// Description: LIN Description file created using VDE

// Created: 04/18/2025 14:02:16

// Author: VDE

LIN_description_file;
LIN_protocol_version = "2.1";
LIN_language_version = "2.1";
LIN_speed = 19.2 kbps;

Nodes {
  Master: VDCU, 10 ms, 0.1 ms ;
  Slaves: RLS, SWS, SGM_S, SGM_IP ;
}

Signals {
  BCM_Dimm_Swt: 4, 10, VDCU, SGM_S, SGM_IP;//Dimmer Switch
  BCM_AirHornSetSts_Sts: 1, 0, VDCU, SGM_IP;//Gas Horn status
  BCM_Temp_Cabin_Slpr: 8, 255, VDCU, SGM_S;//后空调室内温度采集信号 温度范围在-40~100
  BCM_RearHeadlight_Sts: 1, 0, VDCU, SGM_IP;//Rear Light status
  BCM_ACFrontDefrostDisp_Sts: 2, 0, VDCU, SGM_IP;//AC Front Defrost status
  ACBlowerLevelDisp: 4, 0, VDCU, SGM_IP;//风量档位显示
  BCM_PosnLigjtReq_Sts: 1, 0, VDCU, SGM_S, SGM_IP;//Position lamp status
  BCM_ACOffDisp_Sts: 2, 0, VDCU, SGM_S;//AC off status
  BCM_ACTimingRunDisp_Sts: 2, 0, VDCU, SGM_S;//AC Timing Run status
  BCM_ADAS_Sts: 3, 0, VDCU;//ADAS lamp status
  BCM_Status_IGN: 2, 0, VDCU, RLS;//Ignition status 点火开关状态
  BCM_CMD_AutoWiper: 1, 0, VDCU, RLS;//Wiper Switch Auto Enabled 雨刮开关处于自动档位置
  BCM_RQ_FrontWash: 1, 0, VDCU, RLS;//Front Washer Switch is Activated 前洗涤开关处于激活状态
  BCM_ParkPosition: 1, 0, VDCU, RLS;//This signal is set when the wiper blade is in park position. This signal is used by the Sensor to mask overwipes and to check that the wiper motor reacts to the commands from the sensor. 这个信号表示雨刮处于停止位置。这个信号被传感器用来屏蔽过度刮刷，并且确认电机是按照雨量的命令工作的。(此信号在离开ParkPosition或者到达ParkPosition时发出延迟小于100ms)
  BCM_RainSensitivity: 3, 0, VDCU, RLS;//rain sensor sensitivity volume 雨量灵敏度
  BCM_CMD_AutoLight: 1, 0, VDCU, RLS;//Light Switch Auto Enabled 灯光开关处于自动档位置
  BCM_BladesTurningPoint: 1, 0, VDCU, RLS;//This signal is set when the wiper blade is in TurningPoint position. This signal is used by the Sensor to mask overwipes and to check that the wiper motor reacts to the commands from the sensor. 雨刮电机远离停止位置的换向点。
  BCM_SPD_Vehicle: 13, 8190, VDCU, RLS;//Current Vehicle Speed 当前车速
  RLS_MsgCounter: 4, 0, RLS, VDCU;//This is a counter, which will be increased after having sent a message to BCM succesfully 这是一个计数器,当RLS每成功发送给BCM一个消息，就增加1
  RLS_RQ_WiperSPD: 2, 0, RLS, VDCU;//The Sensor requested wiper speed 雨量传感器请求的雨刮速度.
  RLS_RQ_LowBeam: 1, 0, RLS, VDCU;//Auto low beam request 近光灯点亮请求
  RLS_RQ_PositionLamp: 1, 0, RLS, VDCU;//Auto position lamp request 位置灯点亮请求
  RLS_Fault_Rain: 1, 0, RLS, VDCU;//Rain sensor fault status 雨量传感器故障状态
  RLS_Fault_Light: 1, 0, RLS, VDCU;//Light sensor fault status 光亮传感器故障状态
  RLS_REP_Error: 1, 0, RLS, VDCU;//RLS LIN response error RLS通讯故障状态
  RLS_VOLT_Error: 2, 0, RLS, VDCU;//RLS Voltage error RLS检测电池电压错误
  RLS_Brightness_FW: 10, 1023, RLS, VDCU;//The Visible Ambientlight (540nm) measured by Spot FW 可见环境光亮度
  RLS_Rain_Intensity: 4, 0, RLS, VDCU;//This signal delivers information about rain intensity: from 0%(no rain) to 100% (very heavy rain) 降雨强度：从0%到100%
  RLS_BigLamp_Threshold_Nr: 10, 0, RLS, VDCU;//大灯开启阀值信号
  RLS_RainCloseWin_Str: 1, 0, RLS, VDCU;//雨天关窗信号
  RLS_WiperSPD_FuncErr: 2, 0, RLS, VDCU;//雨刮功能安全故障
  RLS_RQ_LowBeam_FuncErr: 2, 0, RLS, VDCU;//近光灯功能安全故障
  RLS_CheckSum: 8, 0, RLS, VDCU;//E2E Checksum
  SGM_S_Unlock_Swt: 2, 0, SGM_S, VDCU;//The Switch of the Unlock
  SGM_S_Lock_Swt: 2, 0, SGM_S, VDCU;//The Switch of the Lock
  SGM_S_WLM_FL_Swt: 3, 0, SGM_S, VDCU;//The Switch of the window
  SGM_S_WLM_FR_Swt: 3, 0, SGM_S, VDCU;//The Switch of the window
  SGM_S_VolumePlus_Swt: 2, 0, SGM_S, VDCU;//The Switch of the AC Volume plus
  SGM_S_VolumeMinus_Swt: 2, 0, SGM_S, VDCU;//The Switch of the AC Volume minus
  SGM_S_ACOnOrOff_Swt: 2, 0, SGM_S, VDCU;//The Switch of the AC on or off
  SGM_S_BlowerLvlPlus_Swt: 2, 0, SGM_S, VDCU;//The Switch of the AC Blowe plus
  SGM_S_BlowerLvlMinus_Swt: 2, 0, SGM_S, VDCU;//The Switch of the AC Blowe minus
  SGM_S_ACTempPlus_Swt: 2, 0, SGM_S, VDCU;//The Switch of the AC Temperature plus
  SGM_S_ACTempMinus_Swt: 2, 0, SGM_S, VDCU;//The Switch of the AC Temperature minus
  SGM_S_ACTimingRun_Swt: 2, 0, SGM_S, VDCU;//The Switch of the AC Timing Run
  SGM_S_CMSStart_Swt: 2, 0, SGM_S, VDCU;//The Switch of the CMS start
  SGM_S_F_LINError: 1, 0, SGM_S, VDCU;//This signal shows one or more failures related to LIN communication.
  SGM_IP_HornType_Swt: 2, 0, SGM_IP, VDCU;//The Switch of the Horn Type
  SGM_IP_RearLight_Swt: 2, 0, SGM_IP, VDCU;//The Switch of the Rear light
  SGM_IP_ACOff_Swt: 2, 0, SGM_IP, VDCU;//The Switch of the AC off
  SGM_IP_BlowerLvlPlus_Swt: 2, 0, SGM_IP, VDCU;//The Switch of the AC Blowe plus
  SGM_IP_BlowerLvlMinus_Swt: 2, 0, SGM_IP, VDCU;//The Switch of the AC Blowe minus
  SGM_IP_ACTempPlus_Swt: 2, 0, SGM_IP, VDCU;//The Switch of the AC Temperature plus
  SGM_IP_ACTempMinus_Swt: 2, 0, SGM_IP, VDCU;//The Switch of the AC Temperature minus
  SGM_IP_ACFrontDefrost_Swt: 2, 0, SGM_IP, VDCU;//The Switch of the AC Front Defrost
  SGM_IP_F_LINError: 1, 0, SGM_IP, VDCU;//This signal shows one or more failures related to LIN communication.
}

Frames {
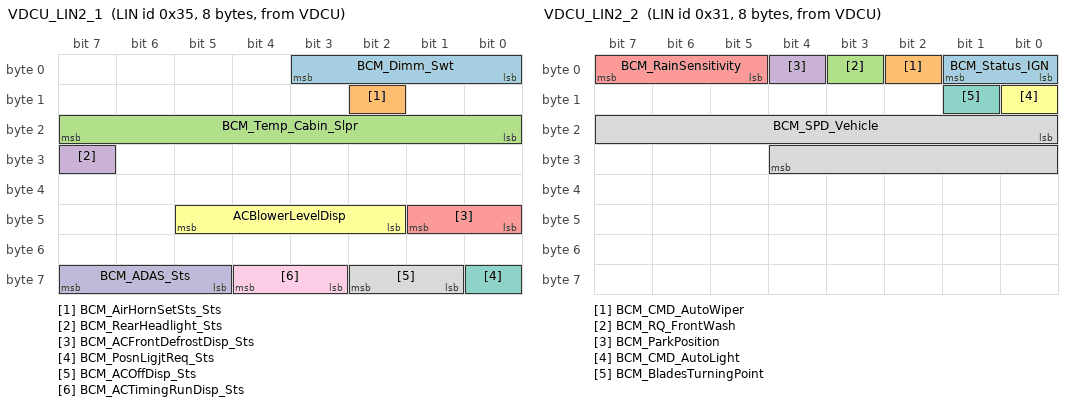
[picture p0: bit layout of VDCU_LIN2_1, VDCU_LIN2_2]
  VDCU_LIN2_1: 0x35, VDCU, 8 {
    BCM_Dimm_Swt, 0 ;
    BCM_AirHornSetSts_Sts, 10 ;
    BCM_Temp_Cabin_Slpr, 16 ;
    BCM_RearHeadlight_Sts, 31 ;
    BCM_ACFrontDefrostDisp_Sts, 40 ;
    ACBlowerLevelDisp, 42 ;
    BCM_PosnLigjtReq_Sts, 56 ;
    BCM_ACOffDisp_Sts, 57 ;
    BCM_ACTimingRunDisp_Sts, 59 ;
    BCM_ADAS_Sts, 61 ;
  }
  VDCU_LIN2_2: 0x31, VDCU, 8 {
    BCM_Status_IGN, 0 ;
    BCM_CMD_AutoWiper, 2 ;
    BCM_RQ_FrontWash, 3 ;
    BCM_ParkPosition, 4 ;
    BCM_RainSensitivity, 5 ;
    BCM_CMD_AutoLight, 8 ;
    BCM_BladesTurningPoint, 9 ;
    BCM_SPD_Vehicle, 16 ;
  }
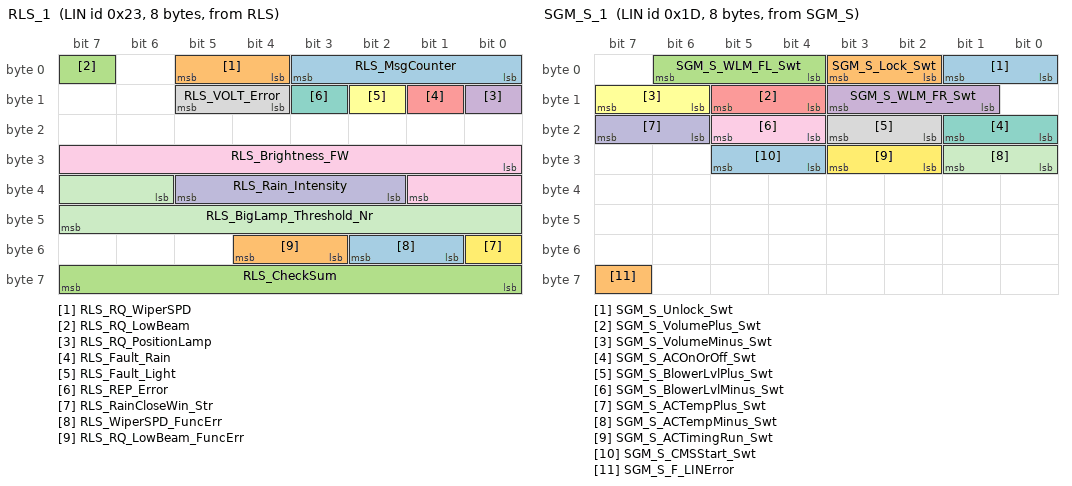
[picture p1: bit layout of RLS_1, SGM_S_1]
  RLS_1: 0x23, RLS, 8 {
    RLS_MsgCounter, 0 ;
    RLS_RQ_WiperSPD, 4 ;
    RLS_RQ_LowBeam, 7 ;
    RLS_RQ_PositionLamp, 8 ;
    RLS_Fault_Rain, 9 ;
    RLS_Fault_Light, 10 ;
    RLS_REP_Error, 11 ;
    RLS_VOLT_Error, 12 ;
    RLS_Brightness_FW, 24 ;
    RLS_Rain_Intensity, 34 ;
    RLS_BigLamp_Threshold_Nr, 38 ;
    RLS_RainCloseWin_Str, 48 ;
    RLS_WiperSPD_FuncErr, 49 ;
    RLS_RQ_LowBeam_FuncErr, 51 ;
    RLS_CheckSum, 56 ;
  }
  SGM_S_1: 0x1D, SGM_S, 8 {
    SGM_S_Unlock_Swt, 0 ;
    SGM_S_Lock_Swt, 2 ;
    SGM_S_WLM_FL_Swt, 4 ;
    SGM_S_WLM_FR_Swt, 9 ;
    SGM_S_VolumePlus_Swt, 12 ;
    SGM_S_VolumeMinus_Swt, 14 ;
    SGM_S_ACOnOrOff_Swt, 16 ;
    SGM_S_BlowerLvlPlus_Swt, 18 ;
    SGM_S_BlowerLvlMinus_Swt, 20 ;
    SGM_S_ACTempPlus_Swt, 22 ;
    SGM_S_ACTempMinus_Swt, 24 ;
    SGM_S_ACTimingRun_Swt, 26 ;
    SGM_S_CMSStart_Swt, 28 ;
    SGM_S_F_LINError, 63 ;
  }
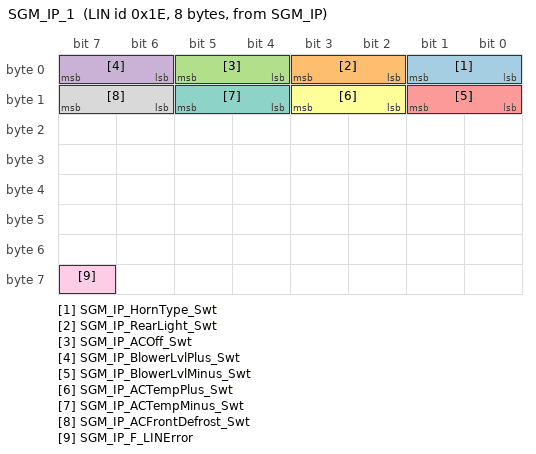
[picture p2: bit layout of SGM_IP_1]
  SGM_IP_1: 0x1E, SGM_IP, 8 {
    SGM_IP_HornType_Swt, 0 ;
    SGM_IP_RearLight_Swt, 2 ;
    SGM_IP_ACOff_Swt, 4 ;
    SGM_IP_BlowerLvlPlus_Swt, 6 ;
    SGM_IP_BlowerLvlMinus_Swt, 8 ;
    SGM_IP_ACTempPlus_Swt, 10 ;
    SGM_IP_ACTempMinus_Swt, 12 ;
    SGM_IP_ACFrontDefrost_Swt, 14 ;
    SGM_IP_F_LINError, 63 ;
  }
}

Node_attributes {
  RLS{
    LIN_protocol = "2.1" ;
    configured_NAD = 35 ;
    initial_NAD = 35 ;
    product_id = 0x0, 0x0, 0 ;
    response_error = RLS_REP_Error ;
    P2_min = 50 ms ;
    ST_min = 0 ms ;
    N_As_timeout = 1000 ms ;
    N_Cr_timeout = 1000 ms ;
    configurable_frames {
      RLS_1 ;
      VDCU_LIN2_2 ;
    }
  }
  SWS{
    LIN_protocol = "2.1" ;
    configured_NAD = 24 ;
    initial_NAD = 24 ;
    product_id = 0x0, 0x0, 0 ;
    P2_min = 50 ms ;
    ST_min = 0 ms ;
    N_As_timeout = 1000 ms ;
    N_Cr_timeout = 1000 ms ;
  }
  SGM_S{
    LIN_protocol = "2.1" ;
    configured_NAD = 29 ;
    initial_NAD = 29 ;
    product_id = 0x0, 0x0, 0 ;
    response_error = SGM_S_F_LINError ;
    P2_min = 50 ms ;
    ST_min = 0 ms ;
    N_As_timeout = 1000 ms ;
    N_Cr_timeout = 1000 ms ;
    configurable_frames {
      SGM_S_1 ;
      VDCU_LIN2_1 ;
    }
  }
  SGM_IP{
    LIN_protocol = "2.1" ;
    configured_NAD = 30 ;
    initial_NAD = 30 ;
    product_id = 0x0, 0x0, 0 ;
    response_error = SGM_IP_F_LINError ;
    P2_min = 50 ms ;
    ST_min = 0 ms ;
    N_As_timeout = 1000 ms ;
    N_Cr_timeout = 1000 ms ;
    configurable_frames {
      SGM_IP_1 ;
      VDCU_LIN2_1 ;
    }
  }
}

Schedule_tables {
 Beacon_LIN1 {
    VDCU_LIN2_1 delay 10 ms ;
    VDCU_LIN2_2 delay 10 ms ;
    SGM_IP_1 delay 10 ms ;
    VDCU_LIN2_2 delay 10 ms ;
    RLS_1 delay 10 ms ;
    SGM_S_1 delay 10 ms ;
  }
}

Signal_encoding_types {
  Enc_VDCU_LIN2_1_BCM_Dimm_Swt {
    physical_value, 0, 10, 10, 0 ;
    logical_value, 0, "Not Request" ;
    logical_value, 1, "10%~100%" ;
    logical_value, 2, "10%~100%" ;
    logical_value, 3, "10%~100%" ;
    logical_value, 4, "10%~100%" ;
    logical_value, 5, "10%~100%" ;
    logical_value, 6, "10%~100%" ;
    logical_value, 7, "10%~100%" ;
    logical_value, 8, "10%~100%" ;
    logical_value, 9, "10%~100%" ;
    logical_value, 10, "10%~100%" ;
    logical_value, 11, "Reserved" ;
    logical_value, 12, "Reserved" ;
    logical_value, 13, "Reserved" ;
    logical_value, 14, "Reserved" ;
    logical_value, 15, "Reserved" ;
  }
  Enc_VDCU_LIN2_1_BCM_AirHornSetSts_Sts {
    physical_value, 0, 1, 1, 0 ;
    logical_value, 0, "ElectricHorn" ;
    logical_value, 1, "AirHorn" ;
  }
  Enc_VDCU_LIN2_1_BCM_Temp_Cabin_Slpr {
    physical_value, 0, 254, 0.5, -40, "℃" ;
  }
  Enc_VDCU_LIN2_1_BCM_RearHeadlight_Sts {
    physical_value, 0, 1, 1, 0 ;
    logical_value, 0, "Lamp Off" ;
    logical_value, 1, "Lamp On" ;
  }
  Enc_VDCU_LIN2_1_BCM_ACFrontDefrostDisp_Sts {
    physical_value, 0, 3, 1, 0 ;
    logical_value, 0, "TakeNoAction" ;
    logical_value, 1, "Off" ;
    logical_value, 2, "On" ;
    logical_value, 3, "Reserved" ;
  }
  Enc_VDCU_LIN2_1_ACBlowerLevelDisp {
    physical_value, 0, 15, 1, 0, "0" ;
  }
  Enc_VDCU_LIN2_1_BCM_PosnLigjtReq_Sts {
    physical_value, 0, 1, 1, 0 ;
    logical_value, 0, "OFF" ;
    logical_value, 1, "ON" ;
  }
  Enc_VDCU_LIN2_1_BCM_ACOffDisp_Sts {
    physical_value, 0, 3, 1, 0 ;
    logical_value, 0, "TakeNoAction" ;
    logical_value, 1, "Off" ;
    logical_value, 2, "On" ;
    logical_value, 3, "Reserved" ;
  }
  Enc_VDCU_LIN2_1_BCM_ACTimingRunDisp_Sts {
    physical_value, 0, 3, 1, 0 ;
    logical_value, 0, "TakeNoAction" ;
    logical_value, 1, "Off" ;
    logical_value, 2, "On" ;
    logical_value, 3, "Reserved" ;
  }
  Enc_VDCU_LIN2_1_BCM_ADAS_Sts {
    physical_value, 0, 7, 1, 0 ;
    logical_value, 0, "Manual" ;
    logical_value, 1, "Auto1（12V_EHPS）" ;
    logical_value, 2, "Auto1（24V_EHPS）" ;
    logical_value, 3, "Reserved" ;
    logical_value, 4, "Reserved" ;
    logical_value, 5, "Reserved" ;
    logical_value, 6, "Reserved" ;
    logical_value, 7, "Reserved" ;
  }
  Enc_VDCU_LIN2_2_BCM_Status_IGN {
    physical_value, 0, 3, 1, 0 ;
    logical_value, 0, "OFF" ;
    logical_value, 1, "ACC" ;
    logical_value, 2, "IGN ON" ;
    logical_value, 3, "IGN Start" ;
  }
  Enc_VDCU_LIN2_2_BCM_CMD_AutoWiper {
    physical_value, 0, 1, 1, 0 ;
    logical_value, 0, "OFF" ;
    logical_value, 1, "ON" ;
  }
  Enc_VDCU_LIN2_2_BCM_RQ_FrontWash {
    physical_value, 0, 1, 1, 0 ;
    logical_value, 0, "No RQ" ;
    logical_value, 1, "RQ FrontWash" ;
  }
  Enc_VDCU_LIN2_2_BCM_ParkPosition {
    physical_value, 0, 1, 1, 0 ;
    logical_value, 0, "Stop not in parking postion" ;
    logical_value, 1, "Stop in parking postion" ;
  }
  Enc_VDCU_LIN2_2_BCM_RainSensitivity {
    physical_value, 0, 7, 1, 0 ;
    logical_value, 0, "Most Insensitive" ;
    logical_value, 1, "More Insensitive" ;
    logical_value, 2, "Insensitive" ;
    logical_value, 3, "Normal" ;
    logical_value, 4, "Sensitive" ;
    logical_value, 5, "More Sensitive(reserved)" ;
    logical_value, 6, "Most Sensitive(reserved)" ;
    logical_value, 7, "Reserved" ;
  }
  Enc_VDCU_LIN2_2_BCM_CMD_AutoLight {
    physical_value, 0, 1, 1, 0 ;
    logical_value, 0, "OFF" ;
    logical_value, 1, "ON" ;
  }
  Enc_VDCU_LIN2_2_BCM_BladesTurningPoint {
    physical_value, 0, 1, 1, 0 ;
    logical_value, 0, "Stop not in TurnPointg pos" ;
    logical_value, 1, "Stop in TurnPoint pos" ;
  }
  Enc_VDCU_LIN2_2_BCM_SPD_Vehicle {
    physical_value, 0, 4800, 0.05625, 0, "Km/h" ;
    logical_value, 8191, "invalid" ;
  }
  Enc_RLS_1_RLS_MsgCounter {
    physical_value, 0, 15, 1, 0 ;
  }
  Enc_RLS_1_RLS_RQ_WiperSPD {
    physical_value, 0, 3, 1, 0 ;
    logical_value, 0, "No wiping" ;
    logical_value, 1, "Low Speed" ;
    logical_value, 2, "High Speed" ;
    logical_value, 3, "Not used" ;
  }
  Enc_RLS_1_RLS_RQ_LowBeam {
    physical_value, 0, 1, 1, 0 ;
    logical_value, 0, "No RQ on Low Beam" ;
    logical_value, 1, "RQ on Low Beam" ;
  }
  Enc_RLS_1_RLS_RQ_PositionLamp {
    physical_value, 0, 1, 1, 0 ;
    logical_value, 0, "No RQ on Position Lamp" ;
    logical_value, 1, "RQ on Position Lamp" ;
  }
  Enc_RLS_1_RLS_Fault_Rain {
    physical_value, 0, 1, 1, 0 ;
    logical_value, 0, "Normal Status" ;
    logical_value, 1, "Status Fault" ;
  }
  Enc_RLS_1_RLS_Fault_Light {
    physical_value, 0, 1, 1, 0 ;
    logical_value, 0, "Normal Status" ;
    logical_value, 1, "Status Fault" ;
  }
  Enc_RLS_1_RLS_REP_Error {
    physical_value, 0, 1, 1, 0 ;
    logical_value, 0, "No error" ;
    logical_value, 1, "Error" ;
  }
  Enc_RLS_1_RLS_VOLT_Error {
    physical_value, 0, 3, 1, 0 ;
    logical_value, 0, "No error" ;
    logical_value, 1, "VOLT_Low" ;
    logical_value, 2, "VOLT_High" ;
    logical_value, 3, "Not used" ;
  }
  Enc_RLS_1_RLS_Brightness_FW {
    physical_value, 0, 1021, 6, 0, "LUX" ;
  }
  Enc_RLS_1_RLS_Rain_Intensity {
    physical_value, 0, 10, 10, 0, "%" ;
  }
  Enc_RLS_1_RLS_BigLamp_Threshold_Nr {
    physical_value, 0, 1021, 6, 0, "LUX" ;
  }
  Enc_RLS_1_RLS_RainCloseWin_Str {
    physical_value, 0, 1, 1, 0 ;
    logical_value, 0, "不关窗" ;
    logical_value, 1, "关窗" ;
  }
  Enc_RLS_1_RLS_WiperSPD_FuncErr {
    physical_value, 0, 3, 1, 0 ;
    logical_value, 0, "正常；" ;
    logical_value, 1, "单点故障（含开关采集类故障、逻辑处理类故障、通讯类故障、驱动类故障等直接影响了功能表现行为的故障）；" ;
    logical_value, 2, "潜伏故障；" ;
    logical_value, 3, "预留。" ;
  }
  Enc_RLS_1_RLS_RQ_LowBeam_FuncErr {
    physical_value, 0, 3, 1, 0 ;
    logical_value, 0, "正常；" ;
    logical_value, 1, "单点故障（含开关采集类故障、逻辑处理类故障、通讯类故障、驱动类故障等直接影响了功能表现行为的故障）；" ;
    logical_value, 2, "潜伏故障；" ;
    logical_value, 3, "预留。" ;
  }
  Enc_RLS_1_RLS_CheckSum {
    physical_value, 0, 255, 1, 0 ;
  }
  Enc_SGM_S_1_SGM_S_Unlock_Swt {
    physical_value, 0, 3, 1, 0 ;
    logical_value, 0, "Not press" ;
    logical_value, 1, "press" ;
    logical_value, 2, "Reserved" ;
    logical_value, 3, "Error" ;
  }
  Enc_SGM_S_1_SGM_S_Lock_Swt {
    physical_value, 0, 3, 1, 0 ;
    logical_value, 0, "Not press" ;
    logical_value, 1, "press" ;
    logical_value, 2, "Reserved" ;
    logical_value, 3, "Error" ;
  }
  Enc_SGM_S_1_SGM_S_WLM_FL_Swt {
    physical_value, 0, 7, 1, 0 ;
    logical_value, 0, "No request" ;
    logical_value, 1, "Driver side driver window manual up" ;
    logical_value, 2, "Driver side driver window manual down" ;
    logical_value, 3, "Driver side driver window auto up" ;
    logical_value, 4, "Driver side driver window auto down" ;
    logical_value, 5, "Reserved" ;
    logical_value, 6, "故障" ;
    logical_value, 7, "无效" ;
  }
  Enc_SGM_S_1_SGM_S_WLM_FR_Swt {
    physical_value, 0, 7, 1, 0 ;
    logical_value, 0, "No request" ;
    logical_value, 1, "Driver side driver window manual up" ;
    logical_value, 2, "Driver side driver window manual down" ;
    logical_value, 3, "Driver side driver window auto up" ;
    logical_value, 4, "Driver side driver window auto down" ;
    logical_value, 5, "Reserved" ;
    logical_value, 6, "故障" ;
    logical_value, 7, "无效" ;
  }
  Enc_SGM_S_1_SGM_S_VolumePlus_Swt {
    physical_value, 0, 3, 1, 0 ;
    logical_value, 0, "Not press" ;
    logical_value, 1, "shortpress" ;
    logical_value, 2, "longpress" ;
    logical_value, 3, "Error" ;
  }
  Enc_SGM_S_1_SGM_S_VolumeMinus_Swt {
    physical_value, 0, 3, 1, 0 ;
    logical_value, 0, "Not press" ;
    logical_value, 1, "shortpress" ;
    logical_value, 2, "longpress" ;
    logical_value, 3, "Error" ;
  }
  Enc_SGM_S_1_SGM_S_ACOnOrOff_Swt {
    physical_value, 0, 3, 1, 0 ;
    logical_value, 0, "Not press" ;
    logical_value, 1, "press" ;
    logical_value, 2, "Reserved" ;
    logical_value, 3, "Error" ;
  }
  Enc_SGM_S_1_SGM_S_BlowerLvlPlus_Swt {
    physical_value, 0, 3, 1, 0 ;
    logical_value, 0, "Not press" ;
    logical_value, 1, "press" ;
    logical_value, 2, "Reserved" ;
    logical_value, 3, "Error" ;
  }
  Enc_SGM_S_1_SGM_S_BlowerLvlMinus_Swt {
    physical_value, 0, 3, 1, 0 ;
    logical_value, 0, "Not press" ;
    logical_value, 1, "press" ;
    logical_value, 2, "Reserved" ;
    logical_value, 3, "Error" ;
  }
  Enc_SGM_S_1_SGM_S_ACTempPlus_Swt {
    physical_value, 0, 3, 1, 0 ;
    logical_value, 0, "Not press" ;
    logical_value, 1, "press" ;
    logical_value, 2, "Reserved" ;
    logical_value, 3, "Error" ;
  }
  Enc_SGM_S_1_SGM_S_ACTempMinus_Swt {
    physical_value, 0, 3, 1, 0 ;
    logical_value, 0, "Not press" ;
    logical_value, 1, "press" ;
    logical_value, 2, "Reserved" ;
    logical_value, 3, "Error" ;
  }
  Enc_SGM_S_1_SGM_S_ACTimingRun_Swt {
    physical_value, 0, 3, 1, 0 ;
    logical_value, 0, "Not press" ;
    logical_value, 1, "press" ;
    logical_value, 2, "Reserved" ;
    logical_value, 3, "Error" ;
  }
  Enc_SGM_S_1_SGM_S_CMSStart_Swt {
    physical_value, 0, 3, 1, 0 ;
    logical_value, 0, "Not press" ;
    logical_value, 1, "press" ;
    logical_value, 2, "Reserved" ;
    logical_value, 3, "Error" ;
  }
  Enc_SGM_S_1_SGM_S_F_LINError {
    physical_value, 0, 1, 1, 0 ;
    logical_value, 0, "Normal" ;
    logical_value, 1, "Error" ;
  }
  Enc_SGM_IP_1_SGM_IP_HornType_Swt {
    physical_value, 0, 3, 1, 0 ;
    logical_value, 0, "Not press" ;
    logical_value, 1, "press" ;
    logical_value, 2, "Reserved" ;
    logical_value, 3, "Error" ;
  }
  Enc_SGM_IP_1_SGM_IP_RearLight_Swt {
    physical_value, 0, 3, 1, 0 ;
    logical_value, 0, "Not press" ;
    logical_value, 1, "press" ;
    logical_value, 2, "Reserved" ;
    logical_value, 3, "Error" ;
  }
  Enc_SGM_IP_1_SGM_IP_ACOff_Swt {
    physical_value, 0, 3, 1, 0 ;
    logical_value, 0, "Not press" ;
    logical_value, 1, "press" ;
    logical_value, 2, "Reserved" ;
    logical_value, 3, "Error" ;
  }
  Enc_SGM_IP_1_SGM_IP_BlowerLvlPlus_Swt {
    physical_value, 0, 3, 1, 0 ;
    logical_value, 0, "Not press" ;
    logical_value, 1, "press" ;
    logical_value, 2, "Reserved" ;
    logical_value, 3, "Error" ;
  }
  Enc_SGM_IP_1_SGM_IP_BlowerLvlMinus_Swt {
    physical_value, 0, 3, 1, 0 ;
    logical_value, 0, "Not press" ;
    logical_value, 1, "press" ;
    logical_value, 2, "Reserved" ;
    logical_value, 3, "Error" ;
  }
  Enc_SGM_IP_1_SGM_IP_ACTempPlus_Swt {
    physical_value, 0, 3, 1, 0 ;
    logical_value, 0, "Not press" ;
    logical_value, 1, "press" ;
    logical_value, 2, "Reserved" ;
    logical_value, 3, "Error" ;
  }
  Enc_SGM_IP_1_SGM_IP_ACTempMinus_Swt {
    physical_value, 0, 3, 1, 0 ;
    logical_value, 0, "Not press" ;
    logical_value, 1, "press" ;
    logical_value, 2, "Reserved" ;
    logical_value, 3, "Error" ;
  }
  Enc_SGM_IP_1_SGM_IP_ACFrontDefrost_Swt {
    physical_value, 0, 3, 1, 0 ;
    logical_value, 0, "Not press" ;
    logical_value, 1, "press" ;
    logical_value, 2, "Reserved" ;
    logical_value, 3, "Error" ;
  }
  Enc_SGM_IP_1_SGM_IP_F_LINError {
    physical_value, 0, 1, 1, 0 ;
    logical_value, 0, "Normal" ;
    logical_value, 1, "Error" ;
  }
}

Signal_representation {
  Enc_VDCU_LIN2_1_BCM_Dimm_Swt: BCM_Dimm_Swt ;
  Enc_VDCU_LIN2_1_BCM_AirHornSetSts_Sts: BCM_AirHornSetSts_Sts ;
  Enc_VDCU_LIN2_1_BCM_Temp_Cabin_Slpr: BCM_Temp_Cabin_Slpr ;
  Enc_VDCU_LIN2_1_BCM_RearHeadlight_Sts: BCM_RearHeadlight_Sts ;
  Enc_VDCU_LIN2_1_BCM_ACFrontDefrostDisp_Sts: BCM_ACFrontDefrostDisp_Sts ;
  Enc_VDCU_LIN2_1_ACBlowerLevelDisp: ACBlowerLevelDisp ;
  Enc_VDCU_LIN2_1_BCM_PosnLigjtReq_Sts: BCM_PosnLigjtReq_Sts ;
  Enc_VDCU_LIN2_1_BCM_ACOffDisp_Sts: BCM_ACOffDisp_Sts ;
  Enc_VDCU_LIN2_1_BCM_ACTimingRunDisp_Sts: BCM_ACTimingRunDisp_Sts ;
  Enc_VDCU_LIN2_1_BCM_ADAS_Sts: BCM_ADAS_Sts ;
  Enc_VDCU_LIN2_2_BCM_Status_IGN: BCM_Status_IGN ;
  Enc_VDCU_LIN2_2_BCM_CMD_AutoWiper: BCM_CMD_AutoWiper ;
  Enc_VDCU_LIN2_2_BCM_RQ_FrontWash: BCM_RQ_FrontWash ;
  Enc_VDCU_LIN2_2_BCM_ParkPosition: BCM_ParkPosition ;
  Enc_VDCU_LIN2_2_BCM_RainSensitivity: BCM_RainSensitivity ;
  Enc_VDCU_LIN2_2_BCM_CMD_AutoLight: BCM_CMD_AutoLight ;
  Enc_VDCU_LIN2_2_BCM_BladesTurningPoint: BCM_BladesTurningPoint ;
  Enc_VDCU_LIN2_2_BCM_SPD_Vehicle: BCM_SPD_Vehicle ;
  Enc_RLS_1_RLS_MsgCounter: RLS_MsgCounter ;
  Enc_RLS_1_RLS_RQ_WiperSPD: RLS_RQ_WiperSPD ;
  Enc_RLS_1_RLS_RQ_LowBeam: RLS_RQ_LowBeam ;
  Enc_RLS_1_RLS_RQ_PositionLamp: RLS_RQ_PositionLamp ;
  Enc_RLS_1_RLS_Fault_Rain: RLS_Fault_Rain ;
  Enc_RLS_1_RLS_Fault_Light: RLS_Fault_Light ;
  Enc_RLS_1_RLS_REP_Error: RLS_REP_Error ;
  Enc_RLS_1_RLS_VOLT_Error: RLS_VOLT_Error ;
  Enc_RLS_1_RLS_Brightness_FW: RLS_Brightness_FW ;
  Enc_RLS_1_RLS_Rain_Intensity: RLS_Rain_Intensity ;
  Enc_RLS_1_RLS_BigLamp_Threshold_Nr: RLS_BigLamp_Threshold_Nr ;
  Enc_RLS_1_RLS_RainCloseWin_Str: RLS_RainCloseWin_Str ;
  Enc_RLS_1_RLS_WiperSPD_FuncErr: RLS_WiperSPD_FuncErr ;
  Enc_RLS_1_RLS_RQ_LowBeam_FuncErr: RLS_RQ_LowBeam_FuncErr ;
  Enc_RLS_1_RLS_CheckSum: RLS_CheckSum ;
  Enc_SGM_S_1_SGM_S_Unlock_Swt: SGM_S_Unlock_Swt ;
  Enc_SGM_S_1_SGM_S_Lock_Swt: SGM_S_Lock_Swt ;
  Enc_SGM_S_1_SGM_S_WLM_FL_Swt: SGM_S_WLM_FL_Swt ;
  Enc_SGM_S_1_SGM_S_WLM_FR_Swt: SGM_S_WLM_FR_Swt ;
  Enc_SGM_S_1_SGM_S_VolumePlus_Swt: SGM_S_VolumePlus_Swt ;
  Enc_SGM_S_1_SGM_S_VolumeMinus_Swt: SGM_S_VolumeMinus_Swt ;
  Enc_SGM_S_1_SGM_S_ACOnOrOff_Swt: SGM_S_ACOnOrOff_Swt ;
  Enc_SGM_S_1_SGM_S_BlowerLvlPlus_Swt: SGM_S_BlowerLvlPlus_Swt ;
  Enc_SGM_S_1_SGM_S_BlowerLvlMinus_Swt: SGM_S_BlowerLvlMinus_Swt ;
  Enc_SGM_S_1_SGM_S_ACTempPlus_Swt: SGM_S_ACTempPlus_Swt ;
  Enc_SGM_S_1_SGM_S_ACTempMinus_Swt: SGM_S_ACTempMinus_Swt ;
  Enc_SGM_S_1_SGM_S_ACTimingRun_Swt: SGM_S_ACTimingRun_Swt ;
  Enc_SGM_S_1_SGM_S_CMSStart_Swt: SGM_S_CMSStart_Swt ;
  Enc_SGM_S_1_SGM_S_F_LINError: SGM_S_F_LINError ;
  Enc_SGM_IP_1_SGM_IP_HornType_Swt: SGM_IP_HornType_Swt ;
  Enc_SGM_IP_1_SGM_IP_RearLight_Swt: SGM_IP_RearLight_Swt ;
  Enc_SGM_IP_1_SGM_IP_ACOff_Swt: SGM_IP_ACOff_Swt ;
  Enc_SGM_IP_1_SGM_IP_BlowerLvlPlus_Swt: SGM_IP_BlowerLvlPlus_Swt ;
  Enc_SGM_IP_1_SGM_IP_BlowerLvlMinus_Swt: SGM_IP_BlowerLvlMinus_Swt ;
  Enc_SGM_IP_1_SGM_IP_ACTempPlus_Swt: SGM_IP_ACTempPlus_Swt ;
  Enc_SGM_IP_1_SGM_IP_ACTempMinus_Swt: SGM_IP_ACTempMinus_Swt ;
  Enc_SGM_IP_1_SGM_IP_ACFrontDefrost_Swt: SGM_IP_ACFrontDefrost_Swt ;
  Enc_SGM_IP_1_SGM_IP_F_LINError: SGM_IP_F_LINError ;
}
